# tviic2d6mddr register map
Vendor: Cypress Semiconductor; Series: tviic2d6mddr; File version: 1.0
CPU: CM7 r0p1, little endian, MPU, FPU, VTOR, 3 interrupt priority bits
Registers are 32-bit, read-write, reset 0x0 unless marked. A register's access mark holds for its fields unless they carry their own. Offsets are from the block's base; [hi:lo] are bit positions; lines under a group give offsets from that group; {n}, {i} and the like mark numbered series; 'fields as' and 'values as' point back to an identical list.

## VIDEOSS0 (part 1 of 18) — Video and Graphics Subsystem IP
Base 0x40A00000
0x00 SUBSS group — Sub Interface
  0x00 VIDEOSSCFG group — Subsystem Control.
    0x00 CTL — IP Control Register
      [31] ENABLED — VIDEOSS enable/disable bit.
        0=DIS (Disable the entire VIDEOSS. System will be held in reset until re-enabled (with the exception of the AHB interface and this register)); 1=EN (Enable VIDEOSS)
    0x04 GFX2D_CTL reset 0x80000000 — IP Control Register for Graphics 2D Core
      [31] GFX2D_ENABLED — If disabled, the Graphics 2D Core is put on reset and its clock input gated.
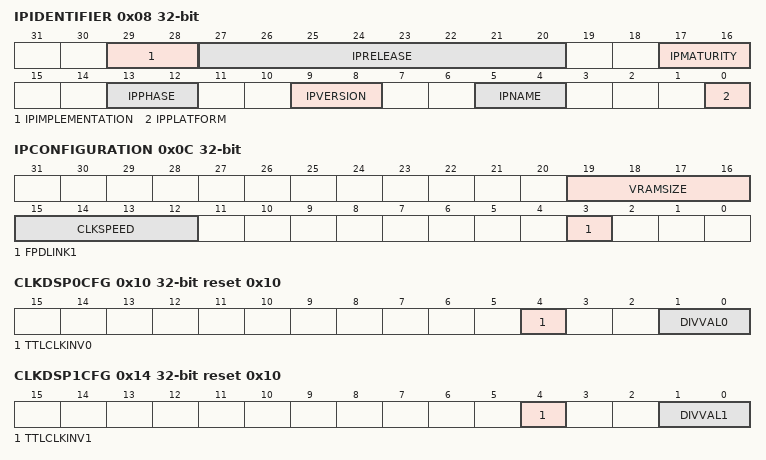
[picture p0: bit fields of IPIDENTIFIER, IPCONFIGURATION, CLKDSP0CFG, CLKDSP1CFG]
    0x08 IPIDENTIFIER ro reset not defined — IP and Design Release Identification
      [29:28] IPIMPLEMENTATION — Implementation type.
        0=RTL (Logic design for FPGA and ASIC synthesis.); 1=TLM (Bit-true and un-timed reference model.)
      [27:20] IPRELEASE — Release ID. This is independently set for each implementation type. The value starts with 0 and is increased for every new release of a an IP project, which is defined by IPName, IPVersion and IPPhase.
      [17:16] IPMATURITY — IP Maturity Status with Chip Integration Cycle targets (CIC). This is independently set for each implementation type.
        0=NONE (Undefined); 1=CPR (Implementation incomplete (for CIC Physical Readiness Review).); 2=CMR (Implementation complete (for CIC Mock Review).); 3=CFR (Verification complete (for CIC Final Handoff Review).)
      [13:12] IPPHASE — IP Phase Number.
      [9:8] IPVERSION — IP Version Number.
      [5:4] IPNAME — Name of IP family.
        0=VIDEOSS (Video and Graphics Subsystem with internal SRAM.); 1=VIDEOSSDDR (Video and Graphics Subsystem for external DDR-SDRAM.); 2=VIDEOSSLITE (Display Composition Subsystem.)
      [0] IPPLATFORM — Name of SOC Platform.
        0=MXS40_S40E (MXS40 High Temperature Variant.)
    0x0C IPCONFIGURATION ro reset not defined — IP Design Configuration
      [19:16] VRAMSIZE — Size of embedded Video RAM in MB. Is 0 if none available.
      [15:12] CLKSPEED — Allowed maximum for core and AXI bus clock frequency.
        0=MHZ_200 (200 MHz); 1=MHZ_250 (250 MHz); 2=MHZ_266 (266 MHz)
      [3] FPDLINK1 — 2nd FPDLink Video Output Interface available (0 = no, 1 = yes)
    0x10 CLKDSP0CFG reset 0x10 — Display 0 Clock Configuration Register
      [4] TTLCLKINV0 — Enable bit for pixel clock inversion on TTL display output interface 0. If enabled, pixel data changes with falling instead of rising clock edge (180 deg phase shift).
      [1:0] DIVVAL0 — Clock Divider Setting (KDIV)
        0=DIV1 (No division); 1=DIV2 (Divide by 2); 2=DIV4 (Divide by 4); 3=DIV8 (Divide by 8)
    0x14 CLKDSP1CFG reset 0x10 — Display 1 Clock Configuration Register
      [4] TTLCLKINV1 — Enable bit for pixel clock inversion on TTL display output interface 1. If enabled, pixel data changes with falling instead of rising clock edge (180 deg phase shift).
      [1:0] DIVVAL1 — Clock Divider Setting (KDIV)
        values as SUBSS.VIDEOSSCFG.CLKDSP0CFG.DIVVAL0
    0x18 CAP0CFG — Capture 0 Configuration
      [1:0] CAP0SRC — Capture Source Selection
        0=TTL (TTL0 interface selected); 1=CSI (CSI-2 (DPHY) Interface Selected); 2=DSP0 (N/A); 3=DSP1 (N/A)
    0x1C FPDLINKCFG — FPDLink Configuration
      [0] FPDLINKSEL — Selects the channel mode for the two FPDlink interfaces.
        0=SINGLE (FPDlink 0 and 1 are operating independently, driven by the two Display Engine 0 and 1.); 1=DUAL (FPDlink 0 and 1 are operating synchronously, both driven by Display Engine 0.)
    0x20 DSP0_CTL — Enable for Display Engine 0
      [31] DSP0_ENABLED — This field, along with CTL.ENABLED above which enables the whole videoss IP, controls the clock and reset release of the DSP0 clock domain.
    0x24 DSP1_CTL — Enable for Display Engine 1
      [31] DSP1_ENABLED — This field, along with CTL.ENABLED above which enables the whole videoss IP, controls the clock and reset release of the DSP1 clock domain.
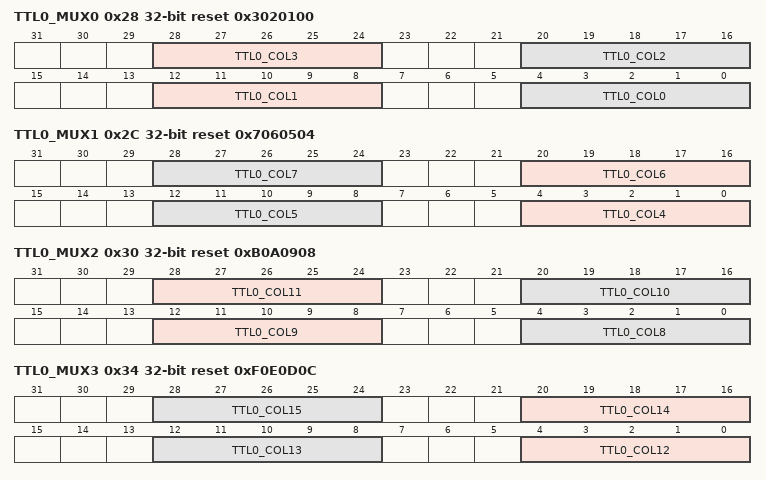
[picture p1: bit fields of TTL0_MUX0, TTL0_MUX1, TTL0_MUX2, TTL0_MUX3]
    0x28 TTL0_MUX0 reset 0x3020100 — Pin multiplexer for capture input from TTL.
      [28:24] TTL0_COL3 — Pin ID for color bit 3 or ITU656 data bit 3.
      [20:16] TTL0_COL2 — Pin ID for color bit 2 or ITU656 data bit 2.
      [12:8] TTL0_COL1 — Pin ID for color bit 1 or ITU656 data bit 1 (10-bit mode only).
      [4:0] TTL0_COL0 — Pin ID for color bit 0 or ITU656 data bit 0 (10-bit mode only).
    0x2C TTL0_MUX1 reset 0x7060504 — Pin multiplexer for capture input from TTL.
      [8n-28:8n-32] TTL0_COL{n} (n=4..7) — Pin ID for color bit {n} or ITU656 data bit {n}.
    0x30 TTL0_MUX2 reset 0xB0A0908 — Pin multiplexer for capture input from TTL.
      [28:24] TTL0_COL11 — Pin ID for color bit 11.
      [20:16] TTL0_COL10 — Pin ID for color bit 10.
      [12:8] TTL0_COL9 — Pin ID for color bit 9 or ITU656 data bit 9.
      [4:0] TTL0_COL8 — Pin ID for color bit 8 or ITU656 data bit 8.
    0x34 TTL0_MUX3 reset 0xF0E0D0C — Pin multiplexer for capture input from TTL.
      [8n-92:8n-96] TTL0_COL{n} (n=12..15) — Pin ID for color bit {n}.
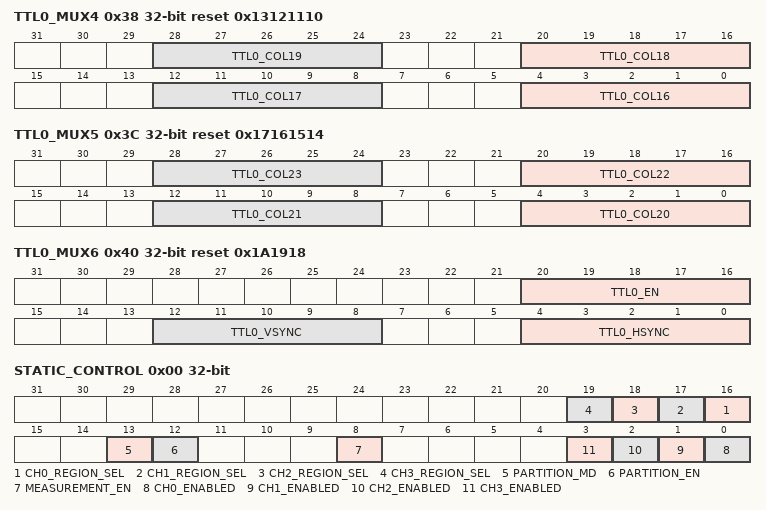
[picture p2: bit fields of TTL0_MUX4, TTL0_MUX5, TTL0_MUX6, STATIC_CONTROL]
    0x38 TTL0_MUX4 reset 0x13121110 — Pin multiplexer for capture input from TTL.
      [8n-124:8n-128] TTL0_COL{n} (n=16..19) — Pin ID for color bit {n}.
    0x3C TTL0_MUX5 reset 0x17161514 — Pin multiplexer for capture input from TTL.
      [8n-156:8n-160] TTL0_COL{n} (n=20..23) — Pin ID for color bit {n}.
    0x40 TTL0_MUX6 reset 0x1A1918 — Pin multiplexer for capture input from TTL.
      [20:16] TTL0_EN — Pin ID for enable signal (active pixels).
      [12:8] TTL0_VSYNC — Pin ID for vertical sync signal.
      [4:0] TTL0_HSYNC — Pin ID for horizontal sync signal.
  0x800 GFXCACHEPIX group — Graphics Cache for Blit and Composition Engine.
    0x00 STATIC_CONTROL
      [n+16] CH{n}_REGION_SEL (n=0..3) — Allocate the cache region for channel {n} (only effective when PARTITION_EN=1)
        0=REGION1ST (The first region); 1=REGION2ND (The second region)
      [13] PARTITION_MD — Cache ways partition mode
        0=MODE11 (Region1st:Region2nd = 1:1); 1=MODE31 (Region1st:Region2nd = 3:1)
      [12] PARTITION_EN — Partition cache ways to two regions
        0=DIS (Disable partition. Whole cache is one region); 1=EN (Enable partition. Two regions.)
      [8] MEASUREMENT_EN — Enable measurement of gfxcache. Corresponding fields are CHX_BYPASS, CHX_MISS and CHX_HIT, OVERFLOW and SAVE_AND_RESET_MEASUREMENTS.
        0=DIS (Disable); 1=EN (Enable)
      [n] CH{n}_ENABLED (n=0..3) — Enable bit for channel {n}
        0=DIS (Disable); 1=EN (Enable)
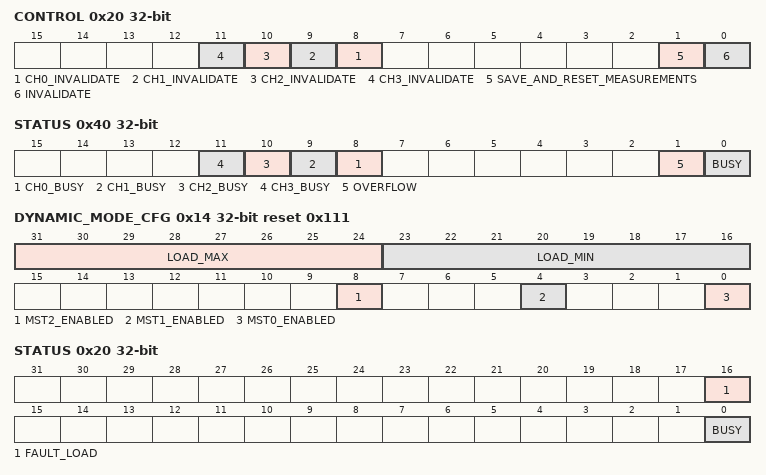
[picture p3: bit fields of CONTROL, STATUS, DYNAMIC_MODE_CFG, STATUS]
    0x20 CONTROL wo reset not defined — Control of the GfxCache.
      [n+8] CH{n}_INVALIDATE (n=0..3) — Triggers invalidation of the cache for channel {n} if CH{n}_ENABLED is enabled.
      [1] SAVE_AND_RESET_MEASUREMENTS — All performance and utilization counters are implemented internally. Writing one to this field provides all measured values to corresponding configurations registers and resets the internal counters.
      [0] INVALIDATE — Triggers invalidation of the cache.
    0x40 STATUS ro reset not defined — Status information
      [n+8] CH{n}_BUSY (n=0..3) — Status of all channels. {n} indicates incomplete transfer.
      [1] OVERFLOW — This bit is set with any counter overflow (equal 0xffffffff). The counter will remain on the overflow value in this case. This field is updated with SAVE_AND_RESET_MEASUREMENTS pulse.
      [0] BUSY — Status of all channels. 1 indicates incomplete transfer.
    {0x80+0xC*k} CH{k}_BYPASS ro reset not defined (k=0..3) — Cache bypass counter.
      [31:0] CH{k}_BYPASS — Count all channel {k} AXI requests trigged to bypass the cache. This field is updated with SAVE_AND_RESET_MEASUREMENTS pulse. See also OVERFLOW bit.
    {0x84+0xC*k} CH{k}_MISS ro reset not defined (k=0..3) — Cache miss counter.
      [31:0] CH{k}_MISS — Count all channel {k} AXI requests passing the cache but request a AXI request to memory. This field is updated with SAVE_AND_RESET_MEASUREMENTS pulse. See also OVERFLOW bit.
    {0x88+0xC*k} CH{k}_HIT ro reset not defined (k=0..3) — Cache hit counter.
      [31:0] CH{k}_HIT — Count all channel {k} AXI requests resulting in a cache hit. This field is updated with SAVE_AND_RESET_MEASUREMENTS pulse. See also OVERFLOW bit.
  0xC00 GFXCACHECMD group — Graphics Cache for Command Sequencer.
    0x00 STATIC_CONTROL
      [8] MEASUREMENT_EN — Enable measurement of gfxcache. Corresponding fields are CHX_BYPASS, CHX_MISS and CHX_HIT, OVERFLOW and SAVE_AND_RESET_MEASUREMENTS.
        0=DIS (Disable); 1=EN (Enable)
      [0] CH0_ENABLED — Enable bit for channel 0
        0=DIS (Disable); 1=EN (Enable)
    0x20 CONTROL wo reset not defined — Control of the GfxCache.
      [8] CH0_INVALIDATE — Triggers invalidation of the cache for channel 0.
      [1] SAVE_AND_RESET_MEASUREMENTS — All performance and utilization counters are implemented internally. Writing one to this field provides all measured values to corresponding configurations registers and resets the internal counters.
      [0] INVALIDATE — Triggers invalidation of the cache.
    0x40 STATUS ro reset not defined — Status information
      [8] CH0_BUSY — Status of all channels. 0 indicates incomplete transfer.
      [1] OVERFLOW — This bit is set with any counter overflow (equal 0xffffffff). The counter will remain on the overflow value in this case. This field is updated with SAVE_AND_RESET_MEASUREMENTS pulse.
      [0] BUSY — Status of all channels. 1 indicates incomplete transfer.
    0x80 CH0_BYPASS ro reset not defined — Cache bypass counter.
      [31:0] CH0_BYPASS — Count all channel 0 AXI requests trigged to bypass the cache. This field is updated with SAVE_AND_RESET_MEASUREMENTS pulse. See also OVERFLOW bit.
    0x84 CH0_MISS ro reset not defined — Cache miss counter.
      [31:0] CH0_MISS — Count all channel 0 AXI requests passing the cache but request a AXI request to memory. This field is updated with SAVE_AND_RESET_MEASUREMENTS pulse. See also OVERFLOW bit.
    0x88 CH0_HIT ro reset not defined — Cache hit counter.
      [31:0] CH0_HIT — Count all channel 0 AXI requests resulting in a cache hit. This field is updated with SAVE_AND_RESET_MEASUREMENTS pulse. See also OVERFLOW bit.
  0x1000 LBCBARBLIT group — Load Balancing Crossbar for Blit Engine.
    0x00 STATIC_CTL — Static control settings.
      [1:0] MODE — Operating mode.
        0=NEUTRAL (The crossbar is deactivated; all slave are directly connected to master ports.); 1=STATIC (Static mapping between slave and master ports.); 2=DYNAMIC_READINESS (Dynamic mapping based on ready status of INFRA request arbiter inputs. The port with longest time since arbiter was busy is selected.); 3=DYNAMIC_LOAD (Dynamic mapping based on outstanding transfer count for INFRA request arbiter outputs. The port with lowest count is selected.)
    0x10 STATIC_MODE_CFG reset 0x210 — Configuration for static arbitration mode.
      [9:8] SLV2_MST — Destination for requests received on slave port 2; value is a master port ID.
      [5:4] SLV1_MST — Destination for requests received on slave port 1; value is a master port ID.
      [1:0] SLV0_MST — Destination for requests received on slave port 0; value is a master port ID.
    0x14 DYNAMIC_MODE_CFG reset 0x111 — Configuration for dynamic arbitration modes.
      [31:24] LOAD_MAX — Maximum threshold for transfer counter in multiple of 4 beats. While the counter for a certain master port is higher than the threshold, the port is disabled; no requests will be routed to it. While all ports have reached that limit, incoming requests are stalled. Setting this field to 0 disables the threshold function. The effect of LOAD_MAX has higher priority than LOAD_MIN.
      [23:16] LOAD_MIN — Minimum threshold for the transfer counter in multiple of 4 beats. While the counter for a certain master port is lower than the threshold, all requests received on the slave port with the same ID are routed to that master, even if other ports have a lower counter value. Setting this field to 0 disables the threshold function. For a disabled master port this field has no effect.
      [8] MST2_ENABLED — Enable bit for master port 0. While disabled, no new requests will be routed to this port.
      [4] MST1_ENABLED — Enable bit for master port 0. While disabled, no new requests will be routed to this port.
      [0] MST0_ENABLED — Enable bit for master port 0. While disabled, no new requests will be routed to this port.
    0x20 STATUS ro reset not defined — Common status information.
      [16] FAULT_LOAD — For debugging purposes only. The bit is set in DYNAMIC_LOAD mode when the transfer counter reaches a value below 0 or above 1023 and keeps value until reset of the IP. It is a fault state, which indicates undefined system behaviour due to invalid state of the AXI interconnect.
      [0] BUSY — When bit is 0, the module is idle and no AXI transactions are pending. It is always 0 in NEUTRAL mode.
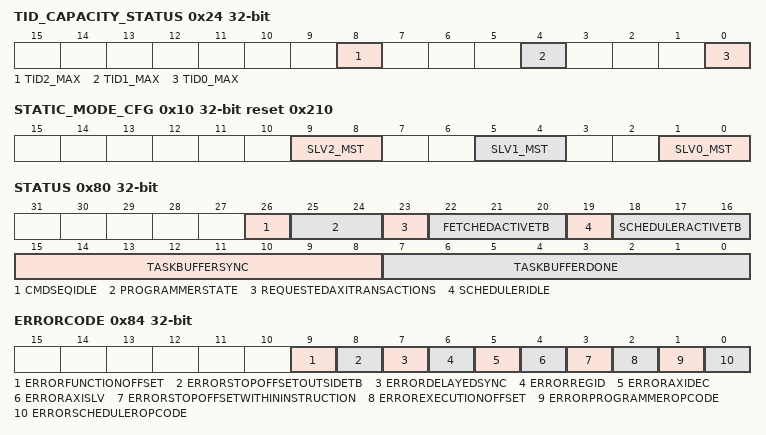
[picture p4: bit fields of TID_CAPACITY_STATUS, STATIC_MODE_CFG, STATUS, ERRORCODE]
    0x24 TID_CAPACITY_STATUS — Outstanding transaction capacity monitor.
      [8] TID2_MAX — When the limit for outstanding transactions is outreached for channel 2, the bit is set. It is cleared by writing a '1' to it.
      [4] TID1_MAX — When the limit for outstanding transactions is outreached for channel 1, the bit is set. It is cleared by writing a '1' to it.
      [0] TID0_MAX — When the limit for outstanding transactions is outreached for channel 0, the bit is set. It is cleared by writing a '1' to it.
  0x1400 LBCBARJPGCMD group — Crossbar for JPEG Decoder, Drawing Engine and Command Sequencer.
    0x00 STATIC_CTL — Static control settings.
      [0] MODE — Operating mode.
        0=NEUTRAL (The crossbar is deactivated; all slave are directly connected to master ports.); 1=STATIC (Static mapping between slave and master ports.)
    0x10 STATIC_MODE_CFG reset 0x210 — Configuration for static arbitration mode.
      fields as SUBSS.LBCBARBLIT.STATIC_MODE_CFG
    0x20 STATUS ro reset not defined — Common status information.
      [0] BUSY — When bit is 0, the module is idle and no AXI transactions are pending. It is always 0 in NEUTRAL mode.
  0x1800 LBCBARVIDEO0 group — Crossbar for Display Layers (FetchWarp1, FetchLayer1, FetchEco1).
    0x00 STATIC_CTL — Static control settings.
      fields as SUBSS.LBCBARJPGCMD.STATIC_CTL
    0x10 STATIC_MODE_CFG reset 0x210 — Configuration for static arbitration mode.
      fields as SUBSS.LBCBARBLIT.STATIC_MODE_CFG
    0x20 STATUS ro reset not defined — Common status information.
      fields as SUBSS.LBCBARJPGCMD.STATUS
  0x1C00 LBCBARVIDEO1 group — Crossbar for Display Layers (FetchDecode0, FetchDecode4, FetchEco4).
    0x00 STATIC_CTL — Static control settings.
      fields as SUBSS.LBCBARJPGCMD.STATIC_CTL
    0x10 STATIC_MODE_CFG reset 0x210 — Configuration for static arbitration mode.
      fields as SUBSS.LBCBARBLIT.STATIC_MODE_CFG
    0x20 STATUS ro reset not defined — Common status information.
      fields as SUBSS.LBCBARJPGCMD.STATUS
  0x40000 GFX2D group — Graphics 2D Core
    0x00 GFX2DCFG group — Graphics 2D Core config
      0x20 INTR_GFX2D — Interrupt cause register
        [23:0] INTR_GFX2D — Interrupt status vector. A bit is set when the related event occurs or the corresponding bit of INTR_GFX2D_SET is written. By writing 1 the corresponding bit is cleared.
      0x24 INTR_GFX2D_SET wo reset not defined — Interrupt set register
        [23:0] INTR_GFX2D_SET — Interrupt set vector. Writing a 1 to this field sets the corresponding bit of INTR_GFX2D.
      0x28 INTR_GFX2D_MASK — Interrupt mask register
        [23:0] INTR_GFX2D_MASK — Interrupt mask vector. Please note that this enable vector does not affect the INTR0 register field. It only affects INTR_GFX2D_MASKED.
      0x2C INTR_GFX2D_MASKED ro reset not defined — Interrupt masked register
        [23:0] INTR_GFX2D_MASKED — Status vector that generates the interrupt to the CPU if at least one bit of this field is set. This field corresponds to the bit-wise AND between INTR_GFX2D and INTR_GFX2D_MASK fields.
      0x30 INTR_CMDSEQ — Interrupt cause register for CmdSeq
        [21:0] INTR_CMDSEQ — Interrupt status vector. A bit is set when the related event occurs or the corresponding bit of INTR_CMDSEQ_SET is written. By writing 1 the corresponding bit is cleared.
      0x34 INTR_CMDSEQ_SET wo reset not defined — Interrupt set register
        [21:0] INTR_CMDSEQ_SET — Interrupt set vector. Writing a 1 to this field sets the corresponding bit of INTR_CMDSEQ.
      {0x40+4l} GENERALPURPOSE[{l}] (l=0..15) reset not defined — General purpose config memory
        [31:0] GENERALPURPOSE — General purpose config memory entry, does not have any function.
    0x10000 CMDSEQ group — Command Sequencer
      {0x0+0xC*l} TASKBUFFERADDRESS{l} (l=0..7) — Task buffer {l} address register
        [31:3] ADDRESSTB{l} — Task buffer {l} base address in multiple of 64-bit words.
      {0x4+0xC*l} TASKBUFFERSIZE{l} (l=0..7) — Task buffer {l} size register
        [15:0] SIZETB{l} — Task buffer {l} size in multiple of 32-bit words. The maximal size of task buffer equals to 4 * (2^16 - 1) bytes. The minimal size required to start execution is 2, because the minimal value of the stop offset is 1 and it has to be smaller then the task buffer size.
      {0x8+0xC*l} TASKBUFFERSTOPOFFSET{l} (l=0..7) — Task buffer {l} stop offset register
        [15:0] STOPOFFSETTB{l} — Task buffer {l} stop offset in multiple of 32-bit words to determine the last valid scheduling instruction. Only scheduling instructions up to this offset are executed or with other words instruction at the StopOffset-1 is the last instruction which is executed.
      {0x60+4l} TASKBUFFEREXECOFFSET{l} ro reset not defined (l=0..7) — Task buffer {l} execute offset register
        [15:0] EXECOFFSETTB{l} — Task buffer {l} execution offset in multiple of 32-bit words. Offset of the scheduling instruction that is to be executed next. Instruction at address = AddressTB{l} has offset zero.
      0x80 STATUS ro reset not defined
        [26] CMDSEQIDLE — CmdSeq is not processing any instructions and there are no outstanding AXI transactions.
        [25:24] PROGRAMMERSTATE — Execution state of programmer
          0=IDLE (When all fetched instructions have been executed and there are no functions scheduled for the execution); 1=SYNC (During execution of the SYNC instruction); 2=ACTIVE (Execution of instructions); 3=AXI_WAIT (There is function scheduled for the execution, but the internal instruction buffer is empty.)
        [23] REQUESTEDAXITRANSACTIONS — There are some outstanding axi transactions that have been requested but are not received yet.
        [22:20] FETCHEDACTIVETB — Task buffer being fetch last in programmer. If programmer is in idle state, the value of this field is not valid.
        [19] SCHEDULERIDLE — Scheduler is not processing any instructions and there are no outstanding AXI transactions.
        [18:16] SCHEDULERACTIVETB — Task buffer being executed in scheduler. If scheduler is in idle state, the value of this field is not valid.
        [15:8] TASKBUFFERSYNC — Each bit corresponds to one task buffer. '1' means that the scheduling of corresponding TB is blocked until some SW or HW state is reached.
        [7:0] TASKBUFFERDONE — Each bit corresponds to one task buffer. '1' means that the ExecOffset equals to the StopOffset
      0x84 ERRORCODE ro reset not defined — Error code register, each field of this register is one bit wide and corresponds to an error event. If the value of this register is zero, than there are no errors.
        [9] ERRORFUNCTIONOFFSET — Function offset provided by the EXEC instruction is outside of task buffer
        [8] ERRORSTOPOFFSETOUTSIDETB — Stop offset value is bigger than or equals to task buffer size. If however both are zero, no error should be raised.
        [7] ERRORDELAYEDSYNC — SYNC is following delayed SYNC in Scheduler
        [6] ERRORREGID — Error accessing an register via id that is not bound to any GPR or SPR register
        [5] ERRORAXIDEC — AXI decoder error has been occurred. SchedulerAddress and ProgrammerAddress have to be evaluated
        [4] ERRORAXISLV — AXI slave error has been occurred. SchedulerAddress and ProgrammerAddress have to be evaluated
        [3] ERRORSTOPOFFSETWITHININSTRUCTION — Stop offset is within instruction in scheduler
        [2] ERROREXECUTIONOFFSET — Execution offset is outside of the task buffer
        [1] ERRORPROGRAMMEROPCODE — Opcode error in programmer
        [0] ERRORSCHEDULEROPCODE — Opcode error in scheduler
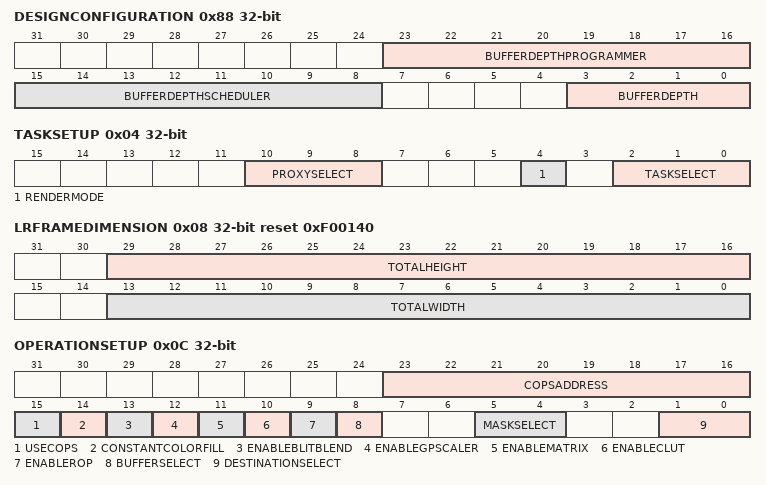
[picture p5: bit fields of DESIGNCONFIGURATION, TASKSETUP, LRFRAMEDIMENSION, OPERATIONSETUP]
      0x88 DESIGNCONFIGURATION ro reset not defined — Provides HW specific information.
        [23:16] BUFFERDEPTHPROGRAMMER — The buffer (axi decouple fifo) size inside of the programmer.
        [15:8] BUFFERDEPTHSCHEDULER — The buffer (axi decouple fifo) size inside of the scheduler.
        [3:0] BUFFERDEPTH — The size of the buffer between the Scheduler and the Programmer.
      0x8C SCHEDULERADDRESS ro reset not defined — Last fetched address of scheduler.
        [31:0] SCHEDULERADDRESS — Last fetched address of scheduler
      0x90 PROGRAMMERADDRESS ro reset not defined — Last fetched address of programmer.
        [31:0] PROGRAMMERADDRESS — Last fetched address of programmer
      {0x94+4l} GPR{l} ro reset not defined (l=0..15) — General purpose Register. (Internal register with id = {l})
        [31:0] GENERALPURPOSEREGISTER{l} — General Purpose Register used internally for CmdSeq and for synchronization with SW.
      0xD4 SPR0 ro reset not defined — Special Purpose Register. (Internal register with id = 16)
        [15:0] LINECOUNTERTB0 — Holds the scheduled line of the frame that is being executed in TB0. The value of this register is routed outside CmdSeq.
      {0xD4+4l} SPR{l} ro reset not defined (l=1..7) — Special Purpose Register (internal register with id = {l+16})
        [15:0] LINECOUNTERTB{l} — Holds the scheduled line of the frame that is being executed in TB{l}. The value of this register is routed outside CmdSeq.
    0x20000 BLITENG group — Blit Engine
      0x00 BLITENGCFG group — Top-Level
        0x00 STATICCONTROL
          [12] DESTINATIONPIXELMEASUREMENTEN — Enable destination pixel counting for LBO and LBO. Corresponding registers are LBODestinationPixelCounter and IBODestinationPixelCounter.
          [11] LBOSOURCEPIXELMEASUREMENTEN — Enable source pixel counting for LBO. Corresponding registers are LBOSourcePixelRGBACounter and LBOSourcePixelAlphaCounter.
          [10] TBUTILIZATIONMEASUREMENTEN — Enable utilization measurement of CmdSeq task buffers (active time for each TB). Corresponding registers are TB[x]UtilizationCounter.
          [9] LBOUTILIZATIONMEASUREMENTEN — Enable utilization measurement of LBO render mode. Corresponding registers are LBOAllFetchesActiveCounter and LBOWaitBlitEngRessourcesCounter.
          [8] BLITENGUTILIZATIONMEASUREMENTEN — Enable utilization measurement of LBO render mode. Corresponding registers are IBOCounter and LBOCounter.
          [5:4] LRSTATUSSELECT — Select pipeline from which to access status register information in line-rendering mode.
          [0] SHDEN — Obsolete. Field value has no effect, shadow registers are always enabled.
        0x04 TASKSETUP — Task configuration register.
          [10:8] PROXYSELECT — Proxy to use for the next operation
            0=OFF (Proxy disabled.); {v}=FETCHLBH{v-1} (Proxy connected to FETCHLBH{v-1}.) (v=1..5)
          [4] RENDERMODE — Blit engine operation mode.
            0=FRAMERENDERING (Frame rendering mode (framebuffer).); 1=LINERENDERING (Line rendering mode (linebuffer).)
          [2:0] TASKSELECT — Select task bank for operation status registers (ypos, ...).
        0x08 LRFRAMEDIMENSION reset 0xF00140 — Dimension of final frame in memory.
          [29:16] TOTALHEIGHT — Frame height (programmed with -1).
          [13:0] TOTALWIDTH — Frame width (programmed with -1).
        0x0C OPERATIONSETUP — Setup for rendering operation.
          [23:16] COPSADDRESS — Address to use in Current Object Processing State (COPS) memory (required for decode operations). Only possible in LBO mode.
          [15] USECOPS — Cops are used for the next fetch operation. If the value is zero, CopsAddress is not evaluated. Only possible in LBO mode.
          [14] CONSTANTCOLORFILL — If this field is set, the selected destination (BufferSelect) will be filled with constant color (ConstantColorRed, ConstantColorGreen, ConstantColorBlue, ConstantAlpha) not using any fetch pipeline. Only possible in LBO mode.
          [13] ENABLEBLITBLEND — Set 1 enable the BlitBlend module. If this field is set
          [12] ENABLEGPSCALER — Set 1 enable GPScaler. This field is ignored for LBO render mode.
          [11] ENABLEMATRIX — Set 1 to enable matrix.
          [10] ENABLECLUT — Set 1 to enable CLUT. This field is ignored for LBO render mode.
          [9] ENABLEROP — Set 1 to enable ROP module. This field is ignored for LBO render mode.
          [8] BUFFERSELECT — Line buffer to render into. This field is ignored for IBO render mode.
            0=RGBA (RGBA buffer.); 1=MASK (MASK buffer.)
          [5:4] MASKSELECT — Select operation for mask buffer. In IBO the buffer is provided via the FETCHMASK; in LBO the buffer is provided via internal ALPHA slice buffer. If the value of both fields this and DestinationSelect is BLEND, OFF is used for this field.
            0=OFF (Mask buffer is not read.); 1=ROP (Mask is connected to raster operation block (secondary). Only possible in IBO mode.); 2=BLEND (Mask is connected to blend operation block. Only possible in LBO mode.); 3=FETCHSRC (Mask is connected to the fetch SRC.)
          [1:0] DESTINATIONSELECT — Select operation for destination buffer. In IBO the buffer is provided via the FETCHDST in LBO the buffer is provided via internal RGBA slice buffer.
            0=OFF (Destination buffer is not read, used for FILL or COPY operations.); 1=ROP (Destination is connected to raster operation block (tertary). Only possible in IBO mode.); 2=BLEND (Destination is connected to blend operation block.); 3=FETCHMASK (Destination fetch is connected to the external input of the fetch MASK, for planar YUV. Only possible in IBO mode.)
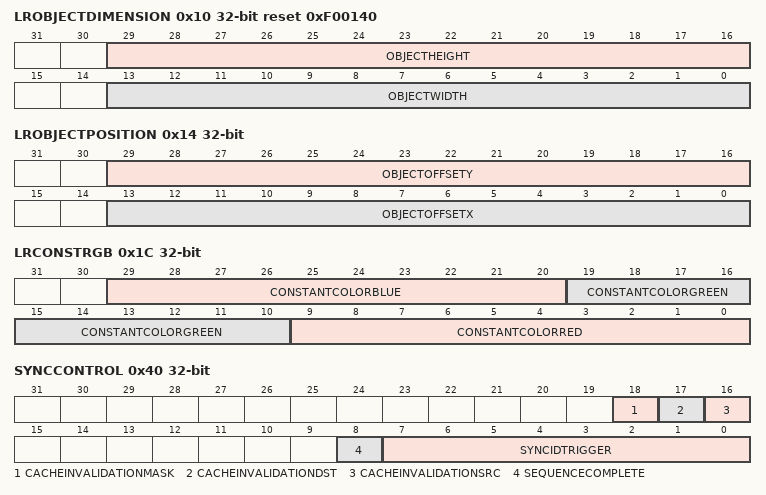
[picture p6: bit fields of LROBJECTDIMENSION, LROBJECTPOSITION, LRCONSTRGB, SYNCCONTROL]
        0x10 LROBJECTDIMENSION reset 0xF00140 — Dimension of object. Only possible in LBO mode
          [29:16] OBJECTHEIGHT — Object height (programmed with -1).
          [13:0] OBJECTWIDTH — Object width (programmed with -1).
        0x14 LROBJECTPOSITION — Position of current object in frame coordinate system. Only possible in LBO mode
          [29:16] OBJECTOFFSETY — Object position in y direction (start at 0).
          [13:0] OBJECTOFFSETX — Object position in x direction (start at 0).
        0x18 LRCONSTALPHA — Constant alpha used to fill buffer w/o fetch unit. Has affect only if ConstantColorFill is set. Only possible in LBO mode.
          [7:0] CONSTANTALPHA — Alpha to be filled to RGBA or Alpha buffer.
        0x1C LRCONSTRGB — Constant color used to fill buffer w/o fetch unit. Has affect only if ConstantColorFill is set and BufferSelect==RGBA. Only possible in LBO mode
          [29:20] CONSTANTCOLORBLUE — Constant blue color to be filled into RGBA buffer.
          [19:10] CONSTANTCOLORGREEN — Constant green color to be filled into RGBA buffer.
          [9:0] CONSTANTCOLORRED — Constant red color to be filled into RGBA buffer.
        {0x20+4m} SYNCIDREQUEST{m} (m=0..7) — Sync ID request register.
          [31:0] SYNCIDREQUEST{m} — Sync ID requested by SW. Will be loaded into SyncIdStatus{m} if SyncIdTrigger[{m}] is set and if/once store operation is done.
        0x40 SYNCCONTROL wo reset not defined — Triggers interrupts for sequence complete of specific TB of global sequence complete interrupt.
          [18] CACHEINVALIDATIONMASK — Triggers invalidation of the GfxCache for FetchMask with the next operation start. Operation can be any IBO or LBO fill, fetch or store.
          [17] CACHEINVALIDATIONDST — Triggers invalidation of the GfxCache for FetchDst with the next operation start. Operation can be any IBO or LBO fill, fetch or store.
          [16] CACHEINVALIDATIONSRC — Triggers invalidation of the GfxCache for FetchSrc with the next operation start. Operation can be any IBO or LBO fill, fetch or store.
          [8] SEQUENCECOMPLETE — Trigger SeqComplete interrupt if BlitEng is idle or the last operation has been completed.
          [7:0] SYNCIDTRIGGER — Trigger SyncIdComplete[0:7] and load SyncIdRequest[0:7] into SyncIdStatus[0:7]. Is executed after store operation is completed or no operation is active on the corresponding TB.
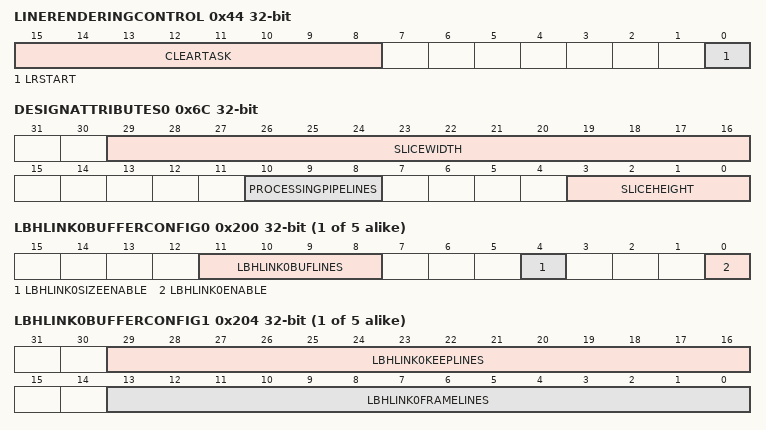
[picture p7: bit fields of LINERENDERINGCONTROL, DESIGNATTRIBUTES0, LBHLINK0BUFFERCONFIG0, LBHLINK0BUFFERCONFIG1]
        0x44 LINERENDERINGCONTROL wo reset not defined — Line rendering operation control register.
          [15:8] CLEARTASK — Clear related registers (ypos, perf) of corresponding TB. Each bit corresponds to one TB.
          [0] LRSTART — Start next source to linebuffer operation.
        0x48 PERFORMANCEMEASUREMENTCONTROL wo reset not defined — Control of the performance and utilitzation measurements.
          [0] SAVEANDRESETMEASUREMENTS — All performance and utilization counters are implemented internally. Writing one to this field provides all measured values to corresponding configurations registers and resets the internal counters.
        {0x4C+4m} SYNCIDSTATUS{m} ro reset not defined (m=0..7) — Sync ID Status register for task {m}.
          [31:0] SYNCIDCOMPLETE{m} — Latest ID completed as requested by SyncIdRequest and SyncIdTrigger with TaskSelect = {m}.
        0x6C DESIGNATTRIBUTES0 ro reset not defined — This register contains attributes of Bliteng. They are not parameters since they cannot be easily changed, however here we still have them to provide some static status on design.
          [29:16] SLICEWIDTH — Returns the maximum width that can be rendered in LBO mode minus one.
          [10:8] PROCESSINGPIPELINES — Returns the maximum number of pixel processing pipelines LBO mode minus one.
          [3:0] SLICEHEIGHT — Returns the slice height mode minus one.
        0x70 DESIGNATTRIBUTES1 ro reset not defined — This register contains attributes of Bliteng. They are not parameters since they cannot be easily changed, however here we still have them to provide some static status on design.
          [13:0] GPSCALERWIDTH — Returns the maximum width that can be rendered in LBO mode minus one.
        0x74 CLOCKCOUNTER ro reset not defined — One of Clock Counter registers.
          [31:0] CLOCKCOUNTER — The internal clock counter is incremented with each 16th clock cycle if any of the measurements are activated. This field is updated with SaveAndResetMeasurements pulse and internal counter is reset.
        0x78 CLOCKCOUNTEROVERFLOW ro reset not defined — One of Clock Counter registers.
          [0] CLOCKCOUNTEROVERFLOW — This bit is set if ClockCounter overflows.
        0x7C IBOACTIVECOUNTER ro reset not defined — One of BlitEng Utilization Measurement registers.
          [31:0] IBOACTIVECOUNTER — The internal LBO counter is incremented with each 16th clock cycle when BlitEng is executing IBO operation and when BlitEngUtilizationMeasurementEn is set. This field is updated with SaveAndResetMeasurements pulse and internal counter is reset.
        0x80 LBOACTIVECOUNTER ro reset not defined — One of BlitEng Utilization Measurement registers.
          [31:0] LBOACTIVECOUNTER — The internal LBO counter is incremented with each 16th clock cycle when BlitEng is executing LBO operation and when BlitEngUtilizationMeasurementEn is set. This field is updated with SaveAndResetMeasurements pulse and internal counter is reset.
        0x84 LBOALLFETCHESACTIVECOUNTER ro reset not defined — One of the LBO utilization measurement registers.
          [31:0] LBOALLFETCHESACTIVECOUNTER — The internal counter is incremented with each 16th clock when all source fetch pipelines are active. Only active in LBO and when LBOUtilizationMeasurementEn is set. This field is updated with SaveAndResetMeasurements pulse and internal counter is reset.
        0x88 LBOWAITBLITENGRESSOURCESCOUNTER ro reset not defined — One of the LBO utilization measurement registers.
          [31:0] LBOWAITBLITENGRESSOURCESCOUNTER — The internal counter is incremented with each 16th clock when the operation has been triggered but is waiting for BlitEng ressources. Only active in LBO and when LBOUtilizationMeasurementEn is set. This field is updated with SaveAndResetMeasurements pulse and internal counter is reset.
        {0x8C+4m} TB{m}ACTIVECOUNTER ro reset not defined (m=0..7) — One of the TB utilization measurement registers. Since TB operations may be overlapping the sum of all TB utilization measurement registers may be higher than clock counter
          [31:0] TB{m}ACTIVECOUNTER — The internal counter is incremented with each 16th clock when there is any ongoing blit operation programmed via TB{m}. Only active when TBUtilizationMeasurementEn is set. This field is updated with SaveAndResetMeasurements pulse and internal counter is reset.
        0xAC LBOSOURCEPIXELRGBACOUNTER ro reset not defined — RGBA source pixel counter for LBO mode
          [31:0] LBOSOURCEPIXELRGBACOUNTER — Provides the number of processed source RGBA pixels which should be multiplied by 256. Only active in LBO and when LBOSourcePixelMeasurementEn is set. This field is updated with SaveAndResetMeasurements pulse and internal counter is reset.
        0xB0 LBOSOURCEPIXELALPHACOUNTER ro reset not defined — Alpha source pixel counter for LBO mode
          [31:0] LBOSOURCEPIXELALPHACOUNTER — Provides the number of processed source alpha pixels which should be multiplied by 256. Only active in LBO and when LBOSourcePixelMeasurementEn is set. This field is updated with SaveAndResetMeasurements pulse and internal counter is reset.
        0xB4 LBODESTINATIONPIXELCOUNTER ro reset not defined — Destination pixel counter for LBO mode
          [31:0] LBODESTINATIONPIXELCOUNTER — Provides the number of processed destination pixels which should be multiplied by 32. In the case of odd width this counter counts one more pixel per line compared to the actual number of pixels. Only active in LBO and when DestinationPixelMeasurementEn is set. This field is updated with SaveAndResetMeasurements pulse and internal counter is reset.
        0xB8 IBODESTINATIONPIXELCOUNTER ro reset not defined — Destination pixel counter for IBO mode
          [31:0] IBODESTINATIONPIXELCOUNTER — Provides the number of processed destination pixels which should be multiplied by 16. Only active in IBO and when DestinationPixelMeasurementEn is set. This field is updated with SaveAndResetMeasurements pulse and internal counter is reset.
        {0x200+0x40*m} LBHLINK{m}BUFFERCONFIG0 (m=0..4) — Line buffer configuration register 0.
          [11:8] LBHLINK{m}BUFLINES — The number of lines in the line buffer in power of two. Max supported number of lines in ringbuffer is 16384 (14pow2=16384). Programming 15 results also in 16384 lines.
          [4] LBHLINK{m}SIZEENABLE — Activates the ring buffer usage. This signal will be provided to the fetch and the store.
          [0] LBHLINK{m}ENABLE — Activates the line-buffer handshake, i.e. will stall the store or the display fetch upon respective condition.
        {0x204+0x40*m} LBHLINK{m}BUFFERCONFIG1 (m=0..4) — Line buffer configuration register 1.
          [29:16] LBHLINK{m}KEEPLINES — Number of lines to keep in the line buffer even if the display fetch is already beyond this line. Required for re-sampling operations that span over several input lines.
          [13:0] LBHLINK{m}FRAMELINES — Height of the frame in number of lines. The height must be identical to the related Blit and Composition Engine setups.
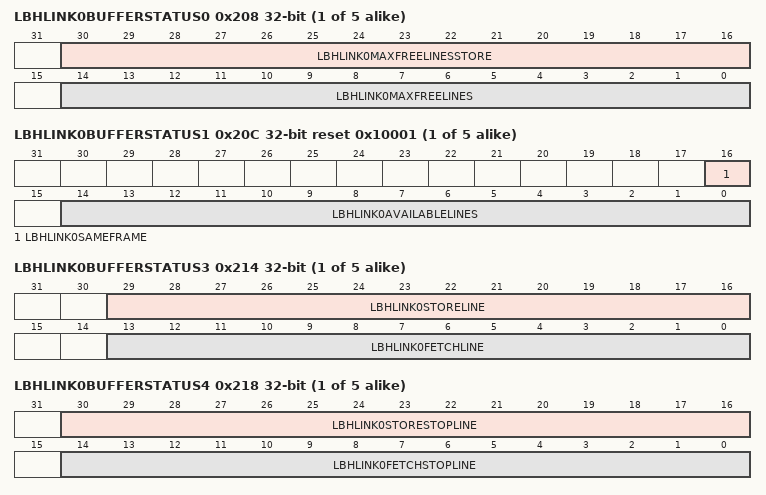
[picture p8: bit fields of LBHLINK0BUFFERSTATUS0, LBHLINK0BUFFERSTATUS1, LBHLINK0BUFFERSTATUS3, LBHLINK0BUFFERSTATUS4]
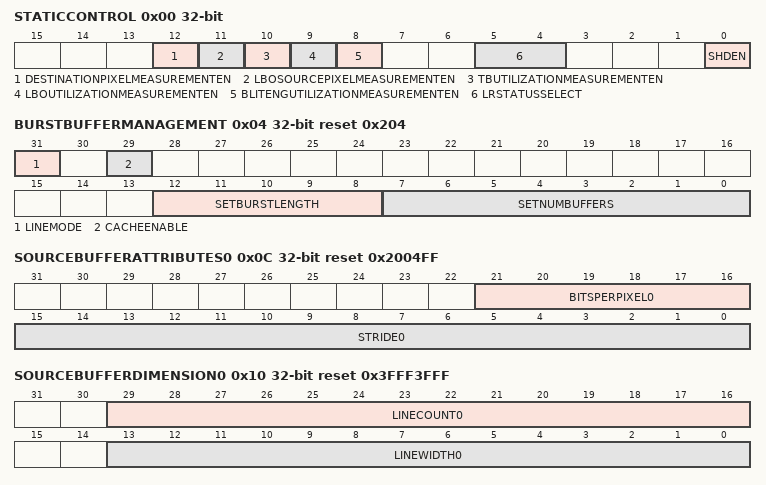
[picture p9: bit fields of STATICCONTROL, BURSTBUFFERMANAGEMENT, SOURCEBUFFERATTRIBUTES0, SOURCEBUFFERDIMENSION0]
        {0x208+0x40*m} LBHLINK{m}BUFFERSTATUS0 (m=0..4) — Buffer status register 0 for the line buffer handshake. Writing to this register has no effect, reading provides the value and simultaneously resets the internal register. The value provided after the first read or if LBH is inactive is not valid.
          [30:16] LBHLINK{m}MAXFREELINESSTORE — The maximal number of free lines in the line buffer that can be written by the store.
          [14:0] LBHLINK{m}MAXFREELINES — The maximal number of free lines in the line buffer that can be scheduled by CmdSeq.
        {0x20C+0x40*m} LBHLINK{m}BUFFERSTATUS1 ro reset 0x10001 (m=0..4) — Buffer status register 1 for the line buffer handshake.
          [16] LBHLINK{m}SAMEFRAME — This status bit indicates if the fetch and the store are processing the same frame. If this bit is zero the store has already switched to the next frame
          [14:0] LBHLINK{m}AVAILABLELINES — The number of lines in the line buffer that the store can write.
        {0x214+0x40*m} LBHLINK{m}BUFFERSTATUS3 ro reset not defined (m=0..4) — Buffer status register 3 for the line buffer handshake.
          [29:16] LBHLINK{m}STORELINE — This field describes the line currently written by the store.
          [13:0] LBHLINK{m}FETCHLINE — This field describes the line currently read by the display fetch.
        {0x218+0x40*m} LBHLINK{m}BUFFERSTATUS4 ro reset not defined (m=0..4) — Buffer status register 4 for the line buffer handshake.
          [30:16] LBHLINK{m}STORESTOPLINE — This field describes the stopline of the store.
          [14:0] LBHLINK{m}FETCHSTOPLINE — This field describes the stopline of the display fetch.
        {0x2000+4m} PALETTE[{m}] (m=0..2047) reset not defined — Shared Palette Memory.
          [23:0] PALETTEENTRY — Shared palette entry with 24-bit. Color format can be defined by Fetch configuration.
      0x4000 FETCHSRC group
        0x00 STATICCONTROL — Common static control options.
          [23:16] BASEADDRESSAUTOUPDATE — Enable flag for continuous shadow load of BaseAddress field for each layer (layer index = bit index). When set to 1 the active BaseAddress configuration is loaded from shadow at start of each frame. This update is then executed independently from other RWS type fields. ShdEn must be enabled for this mode. When the flag is enabled for layer 0, also the FieldId0 shadow is automatically loaded.
          [0] SHDEN — Enables shadowing of all RWS type registers (0=write_through, 1=shadowed).
        0x04 BURSTBUFFERMANAGEMENT reset 0x204 — AXI interface buffer management register
          [31] LINEMODE — Fetch buffer cache control.
            0=DISPLAY (Mandatory setting for operation in the Display Controller. Works also for Blit Engine with marginal performance impact.); 1=BLIT (Recommended setting for operation in the Blit Engine.)
          [29] CACHEENABLE — If enabled, all AXI transactions are marked to be cacheable.
          [12:8] SETBURSTLENGTH — Set this to the burst length that should be used on the AXI interface. SetNumBuffers * SetBurstLength has to be smaller or equal to ManagedBurstBuffers * BurstLengthForMaxBuffers and that bursts larger than 16 are not possible on the axi interface. Only a power of two may be specified as burst length.
          [7:0] SETNUMBUFFERS — Set this to the number of bursts that should be buffered. SetNumBuffers has to be smaller or equal to ManagedBurstBuffers and SetNumBuffers * SetBurstLength has to be smaller or equal to ManagedBurstBuffers * BurstLengthForMaxBuffers. Must be a power of 2. The minimum allowed settings is 4 except for the FetchEco derivate which has a minimum allowed setting of 2.
        0x08 BASEADDRESS0 — Source buffer base address of layer 0.
          [31:0] BASEADDRESS0 — Byte aligned start address of the layer source buffer. For a pixel width of 32 bits or DECODE operations BaseAddress bits 1 downto 0 have to be 0 and for a pixel width of 16 bit BaseAddress[0] has to be 0.
        0x0C SOURCEBUFFERATTRIBUTES0 reset 0x2004FF — Source buffer attributes for layer 0.
          [21:16] BITSPERPIXEL0 — Number of bits per pixel in the source buffer. Must be 1, 2, 4, 8, 16, 18, 24 or 32. [Exception] FetchEco does not support 18 and 24.
          [15:0] STRIDE0 — Source buffer stride of the layer in bytes minus one, used for address generation. For a pixel width of 32 bits Stride has to be dividable by 4 and given minus one and for a pixel width of 16 bit Stride has to be dividable by two and given minus one.
        0x10 SOURCEBUFFERDIMENSION0 reset 0x3FFF3FFF — Source buffer dimension of layer 0.
          [29:16] LINECOUNT0 — Number of lines of the source buffer of the layer minus one.
          [13:0] LINEWIDTH0 — Width of the source buffer of the layer in pixels minus one.
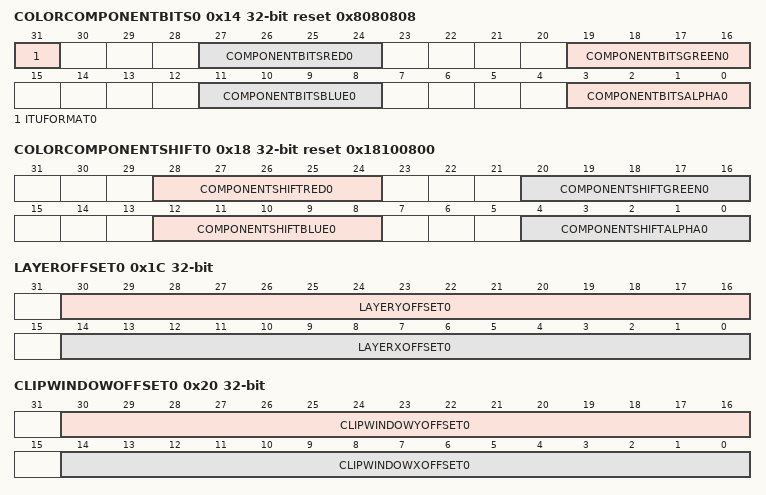
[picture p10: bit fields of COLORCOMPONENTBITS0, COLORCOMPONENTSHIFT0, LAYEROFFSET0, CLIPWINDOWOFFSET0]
        0x14 COLORCOMPONENTBITS0 reset 0x8080808 — Size of color components for RGB, YUV and index formats (layer 0).
          [31] ITUFORMAT0 — When ComponentBitsRed/Green/Blue is set to 10 and this mode enabled (value 1), then input format is considered 8.2 instead of 10.0 bits (max color is 1020 instead of 1023). This is compliant to ITU 656 standard.
          [27:24] COMPONENTBITSRED0 — Red, Y (luma) and palette index.
          [19:16] COMPONENTBITSGREEN0 — Green and U (chroma).
          [11:8] COMPONENTBITSBLUE0 — Blue and V (chroma).
          [3:0] COMPONENTBITSALPHA0 — Alpha.
        0x18 COLORCOMPONENTSHIFT0 reset 0x18100800 — Bit position of color components for RGB, YUV and index formats (layer 0).
          [28:24] COMPONENTSHIFTRED0 — Red, Y (luma) and palette index.
          [20:16] COMPONENTSHIFTGREEN0 — Green and U (chroma).
          [12:8] COMPONENTSHIFTBLUE0 — Blue and V (chroma).
          [4:0] COMPONENTSHIFTALPHA0 — Alpha.
        0x1C LAYEROFFSET0 — Position of layer 0 within the destination frame.
          [30:16] LAYERYOFFSET0 — Vertical offset (Y). (format is signed integer)
          [14:0] LAYERXOFFSET0 — Horizontal offset (X). (format is signed integer)
        0x20 CLIPWINDOWOFFSET0 — Clip window position for layer 0.
          [30:16] CLIPWINDOWYOFFSET0 — Vertical position (Y). (format is signed integer)
          [14:0] CLIPWINDOWXOFFSET0 — Horizontal position (X). (format is signed integer)
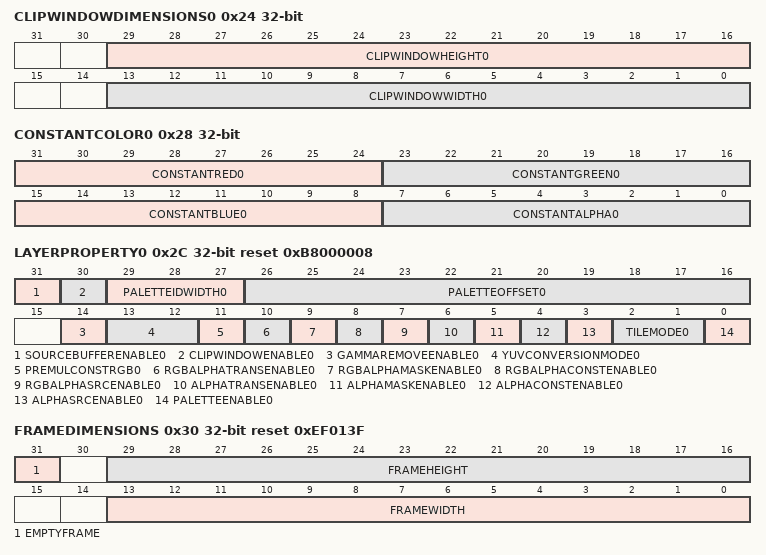
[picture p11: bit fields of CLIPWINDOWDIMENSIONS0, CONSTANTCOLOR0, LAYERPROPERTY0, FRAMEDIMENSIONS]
        0x24 CLIPWINDOWDIMENSIONS0 — Clip window size for layer 0.
          [29:16] CLIPWINDOWHEIGHT0 — Height.
          [13:0] CLIPWINDOWWIDTH0 — Width.
        0x28 CONSTANTCOLOR0 — Constant color for layer 0.
          [31:24] CONSTANTRED0 — Red and Y (luma).
          [23:16] CONSTANTGREEN0 — Green and U (chroma).
          [15:8] CONSTANTBLUE0 — Blue and V (chroma).
          [7:0] CONSTANTALPHA0 — Alpha.
        0x2C LAYERPROPERTY0 reset 0xB8000008 — Common properties of layer 0.
          [31] SOURCEBUFFERENABLE0 — Value 1 enables the source buffer for this layer. When disabled the tiling color is used only (TileMode TILE_PAD not allowed).
          [30] CLIPWINDOWENABLE0 — Value 1 enables the clip window for this layer. Pixels outside the clip window get the clip color, pixels inside the source or tiling color.
          [29:27] PALETTEIDWIDTH0 — Number minus one of least significant bits of pixel data read from the source buffer that are used as index value for color palette look-up.
          [26:16] PALETTEOFFSET0 — Palette may contain multiple areas. This offset shows to the starting position of the currently used area.
          [14] GAMMAREMOVEENABLE0 — Value 1 enables the stage to remove a gamma from RGB components.
          [13:12] YUVCONVERSIONMODE0 — Enables different kind of YUV to RGB conversions.
            0=OFF (No conversion.); 1=ITU601 (Conversion from YCbCr (YUV) to RGB according to ITU recommendation BT.601-6 (standard definition TV). Input range is 16..235 for Y and 16..240 for U/V.); 2=ITU601_FR (Conversion from YCbCr (YUV) to RGB according to ITU recommendation BT.601-6, but assuming full range YUV inputs (0..255). Most typically used for computer graphics (e.g. for JPEG encoding).); 3=ITU709 (Conversion from YCbCr (YUV) to RGB according to ITU recommendation BT.709-5 part 2 (high definition TV). Input range is 16..235 for Y and 16..240 for U/V.)
          [11] PREMULCONSTRGB0 — When enabled (value 1) the values given by ConstantRed/Green/Blue are used instead of alpha for source RGB pre-multiply. Settings RGBAlphaSrc/Const/Mask/TransEnable have no effect then.
          [10] RGBALPHATRANSENABLE0 — Value 1 enables transparent alpha (0 or 1 depending on RGB matching ConstantColor setting) for RGB pre-multiply. When disabled transparent alpha is set to 1.
          [9] RGBALPHAMASKENABLE0 — Value 1 enables mask alpha (read by another Fetch unit from a separate alpha layer) for RGB pre-multiply. When disabled mask alpha is set to 1. Alpha mask input must be enabled for this field to have effect.
          [8] RGBALPHACONSTENABLE0 — Value 1 enables constant alpha (ConstAlpha fields) for RGB pre-multiply. When disabled constant alpha is set to 1.
          [7] RGBALPHASRCENABLE0 — Value 1 enables source alpha (stored together with color component in the source buffer) for RGB pre-multiply. When disabled source alpha is set to 1.
          [6] ALPHATRANSENABLE0 — Value 1 enables transparent alpha for computing the output alpha. When disabled transparent alpha is set to 1.
          [5] ALPHAMASKENABLE0 — Value 1 enables mask alpha for computing the output alpha. When disabled mask alpha is set to 1.
          [4] ALPHACONSTENABLE0 — Value 1 enables constant alpha for computing the output alpha. When disabled constant alpha is set to 1.
          [3] ALPHASRCENABLE0 — Value 1 enables source alpha for computing the output alpha. When disabled source alpha is set to 1.
          [2:1] TILEMODE0 — Select the tile mode for pixels outside the source buffer. Clip color (0,0,0,0) takes precedence if a pixel becomes subject to both tiling and clipping.
            0=TILE_FILL_ZERO (Use zero value); 1=TILE_FILL_CONSTANT (Use constant color register value); 2=TILE_PAD (Use closest pixel from source buffer. Must not be used for DECODE or YUV422 operations or when SourceBufferEnable is 0.); 3=TILE_PAD_ZERO (Use closest pixel from source buffer but zero for alpha component. Must not be used for DECODE or YUV422 operations or when SourceBufferEnable is 0.)
          [0] PALETTEENABLE0 — Enables (value = 1) a color palette with 8 bits input and 24 bits output. Lower bits of the lookup index are read from memory (PaletteIdWidth0), upper bits are set to index of this layer. Palette output is extended by upper bits of index word read from memory (e.g. to store alpha together with index). Result is mapped to color channels according to ColorComponentBits/Shift settings.
        0x30 FRAMEDIMENSIONS reset 0xEF013F — Output frame dimension.
          [31] EMPTYFRAME — When enabled output frame is empty. FrameWidth/Height settings have no effect then. Can be used to load shadows or to generate synchronization signals only (frame/sequence complete). If enabled, InputSelect must be set to INACTIVE.
          [29:16] FRAMEHEIGHT — Frame height minus one.
          [13:0] FRAMEWIDTH — Frame width minus one.
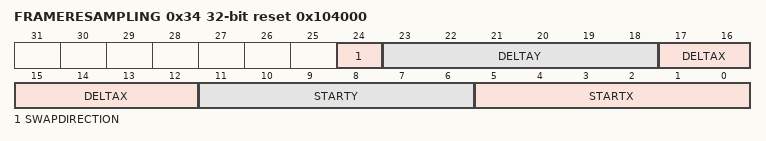
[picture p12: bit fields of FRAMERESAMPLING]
        0x34 FRAMERESAMPLING reset 0x104000 — Resampling options for output frame.
          [24] SWAPDIRECTION — Swaps X and Y directions for re-sampling. When enabled (= 1) DeltaY is applied for horizontal and DeltaX for vertical step on destination frame.
          [23:18] DELTAY — Increment of Y coordinate for vertical step in destination frame. (format is signed fix-point 4.2)
          [17:12] DELTAX — Increment of X coordinate for horizontal step in destination frame. (format is signed fix-point 4.2)
          [11:6] STARTY — Y coordinate of first sample point relative to origin. (format is signed fix-point 4.2)
          [5:0] STARTX — X coordinate of first sample point relative to origin. (format is signed fix-point 4.2)
